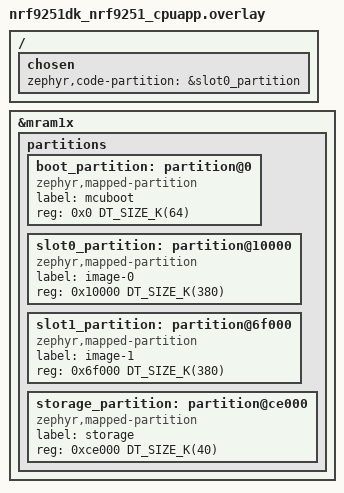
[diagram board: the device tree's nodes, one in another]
/*
 * Copyright (c) 2026 Nordic Semiconductor ASA
 *
 * SPDX-License-Identifier: LicenseRef-Nordic-5-Clause
 */

&mram1x {
	/delete-node/ partitions;

	partitions {
		ranges;
		#address-cells = <1>;
		#size-cells = <1>;

		boot_partition: partition@0 {
			compatible = "zephyr,mapped-partition";
			label = "mcuboot";
			reg = <0x0 DT_SIZE_K(64)>;
		};

		slot0_partition: partition@10000 {
			compatible = "zephyr,mapped-partition";
			label = "image-0";
			reg = <0x10000 DT_SIZE_K(380)>;
		};

		slot1_partition: partition@6f000 {
			compatible = "zephyr,mapped-partition";
			label = "image-1";
			reg = <0x6f000 DT_SIZE_K(380)>;
		};

		storage_partition: partition@ce000 {
			compatible = "zephyr,mapped-partition";
			label = "storage";
			reg = <0xce000 DT_SIZE_K(40)>;
		};
	};
};

/ {
	chosen {
		zephyr,code-partition = &slot0_partition;
	};
};
